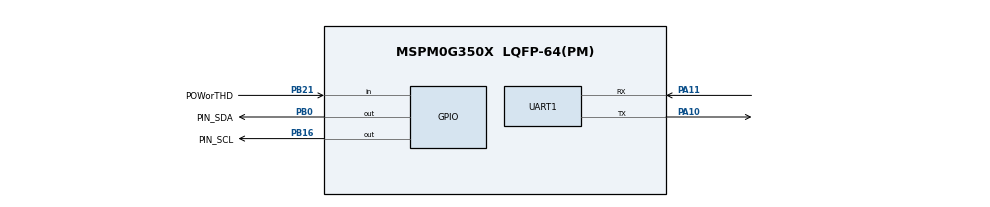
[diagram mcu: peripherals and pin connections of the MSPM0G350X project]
/**
 * @cliArgs --device "MSPM0G350X" --package "LQFP-64(PM)" --part "Default" --product "mspm0_sdk@2.01.00.03"
 * @versions {"tool":"1.20.0+3587"}
 */

/**
 * Import the modules used in this configuration.
 */
const ADC12         = scripting.addModule("/ti/driverlib/ADC12", {}, false);
const ADC121        = ADC12.addInstance();
const Board         = scripting.addModule("/ti/driverlib/Board");
const GPIO          = scripting.addModule("/ti/driverlib/GPIO", {}, false);
const GPIO1         = GPIO.addInstance();
const GPIO2         = GPIO.addInstance();
const SYSCTL        = scripting.addModule("/ti/driverlib/SYSCTL");
const TIMER         = scripting.addModule("/ti/driverlib/TIMER", {}, false);
const TIMER1        = TIMER.addInstance();
const UART          = scripting.addModule("/ti/driverlib/UART", {}, false);
const UART1         = UART.addInstance();
const ProjectConfig = scripting.addModule("/ti/project_config/ProjectConfig");

/**
 * Write custom configuration values to the imported modules.
 */
const gate8  = system.clockTree["MFPCLKGATE"];
gate8.enable = true;

const mux4       = system.clockTree["EXHFMUX"];
mux4.inputSelect = "EXHFMUX_XTAL";

const pinFunction4     = system.clockTree["HFXT"];
pinFunction4.inputFreq = 40;
pinFunction4.enable    = true;

ADC121.$name                             = "ADC12_0";
ADC121.sampClkDiv                        = "DL_ADC12_CLOCK_DIVIDE_8";
ADC121.powerDownMode                     = "DL_ADC12_POWER_DOWN_MODE_MANUAL";
ADC121.trigSrc                           = "DL_ADC12_TRIG_SRC_EVENT";
ADC121.sampClkSrc                        = "DL_ADC12_CLOCK_ULPCLK";
ADC121.subChanID                         = 1;
ADC121.configureDMA                      = true;
ADC121.enabledInterrupts                 = ["DL_ADC12_INTERRUPT_DMA_DONE"];
ADC121.interruptPriority                 = "1";
ADC121.sampleTime0                       = "250 ns";
ADC121.adcMem0trig                       = "DL_ADC12_TRIGGER_MODE_TRIGGER_NEXT";
ADC121.repeatMode                        = true;
ADC121.samplingOperationMode             = "sequence";
ADC121.endAdd                            = 1;
ADC121.enabledDMATriggers                = ["DL_ADC12_DMA_MEM10_RESULT_LOADED"];
ADC121.sampCnt                           = 6;
ADC121.adcMem1trig                       = "DL_ADC12_TRIGGER_MODE_TRIGGER_NEXT";
ADC121.enableFIFO                        = true;
ADC121.adcMem1chansel                    = "DL_ADC12_INPUT_CHAN_2";
ADC121.peripheral.$assign                = "ADC0";
ADC121.adcPin0Config.$name               = "ti_driverlib_gpio_GPIOPinGeneric1";
ADC121.DMA_CHANNEL.$name                 = "DMA_CH0";
ADC121.DMA_CHANNEL.addressMode           = "f2b";
ADC121.DMA_CHANNEL.configureTransferSize = true;
ADC121.DMA_CHANNEL.transferMode          = "FULL_CH_REPEAT_SINGLE";
ADC121.DMA_CHANNEL.transferSize          = 512;
ADC121.adcPin2Config.$name               = "ti_driverlib_gpio_GPIOPinGeneric0";


GPIO1.$name                         = "GPIO_OLED";
GPIO1.port                          = "PORTB";
GPIO1.associatedPins.create(2);
GPIO1.associatedPins[0].$name       = "PIN_SCL";
GPIO1.associatedPins[0].pin.$assign = "PB16";
GPIO1.associatedPins[1].$name       = "PIN_SDA";
GPIO1.associatedPins[1].pin.$assign = "PB0";

GPIO2.$name                              = "GPIO_IN";
GPIO2.associatedPins.create(2);
GPIO2.associatedPins[0].internalResistor = "PULL_UP";
GPIO2.associatedPins[0].$name            = "POWorTHD";
GPIO2.associatedPins[0].direction        = "INPUT";
GPIO2.associatedPins[0].interruptEn      = true;
GPIO2.associatedPins[0].polarity         = "FALL";
GPIO2.associatedPins[0].pin.$assign      = "PB21";
GPIO2.associatedPins[1].internalResistor = "PULL_UP";
GPIO2.associatedPins[1].$name            = "CLRorSet";
GPIO2.associatedPins[1].direction        = "INPUT";

SYSCTL.forceDefaultClkConfig = true;
SYSCTL.clockTreeEn           = true;
SYSCTL.useHFCLK_Manual       = true;

TIMER1.$name                       = "TIMER_0";
TIMER1.timerMode                   = "PERIODIC";
TIMER1.event1PublisherChannel      = 1;
TIMER1.event1ControllerInterruptEn = ["ZERO_EVENT"];
TIMER1.timerStartTimer             = true;
TIMER1.event2ControllerInterruptEn = ["ZERO_EVENT"];
TIMER1.counterZero                 = true;
TIMER1.timerPeriod                 = "1us";

UART1.$name                    = "UART_0";
UART1.targetBaudRate           = 115200;
UART1.peripheral.rxPin.$assign = "PA11";
UART1.peripheral.txPin.$assign = "PA10";
UART1.txPinConfig.$name        = "ti_driverlib_gpio_GPIOPinGeneric10";
UART1.rxPinConfig.$name        = "ti_driverlib_gpio_GPIOPinGeneric11";

ProjectConfig.genLibCMSIS = true;

/**
 * Pinmux solution for unlocked pins/peripherals. This ensures that minor changes to the automatic solver in a future
 * version of the tool will not impact the pinmux you originally saw.  These lines can be completely deleted in order to
 * re-solve from scratch.
 */
pinFunction4.peripheral.$suggestSolution           = "SYSCTL";
pinFunction4.peripheral.hfxInPin.$suggestSolution  = "PA5";
pinFunction4.peripheral.hfxOutPin.$suggestSolution = "PA6";
ADC121.peripheral.adcPin0.$suggestSolution         = "PA27";
ADC121.peripheral.adcPin2.$suggestSolution         = "PA25";
ADC121.DMA_CHANNEL.peripheral.$suggestSolution     = "DMA_CH0";
Board.peripheral.$suggestSolution                  = "DEBUGSS";
Board.peripheral.swclkPin.$suggestSolution         = "PA20";
Board.peripheral.swdioPin.$suggestSolution         = "PA19";
GPIO2.associatedPins[1].pin.$suggestSolution       = "PB13";
TIMER1.peripheral.$suggestSolution                 = "TIMA0";
UART1.peripheral.$suggestSolution                  = "UART0";
